# STM32H7A3 register map
File version: 3.4
CPU: CM7 r0p1, little endian, MPU, FPU, 4 interrupt priority bits
Registers are 32-bit, read-write, reset 0x0 unless marked. A register's access mark holds for its fields unless they carry their own. Offsets are from the block's base; [hi:lo] are bit positions; {n}, {i} and the like mark numbered series.

## TAMP — Tamper and backup
Base 0x58004400
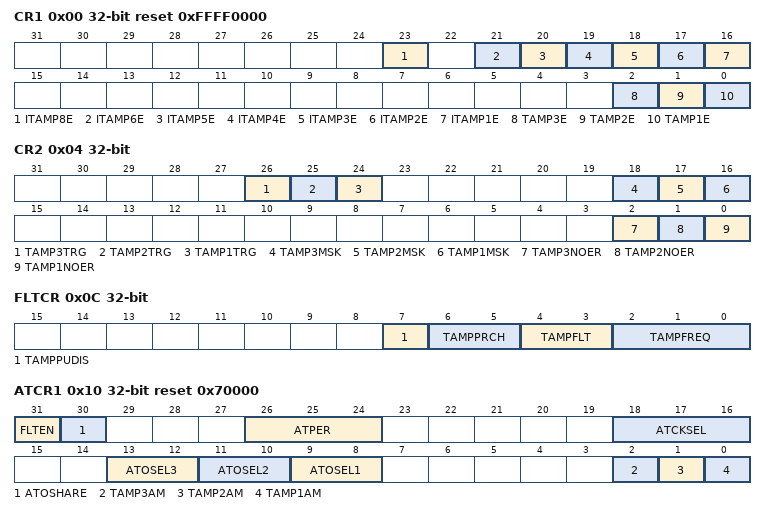
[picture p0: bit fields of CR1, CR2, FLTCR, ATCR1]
0x00 CR1 reset 0xFFFF0000 — TAMP control register 1
  [23] ITAMP8E — Internal tamper 8 enable: monotonic counter overflow
  [21] ITAMP6E — Internal tamper 6 enable: ST manufacturer readout
  [20] ITAMP5E — Internal tamper 5 enable: RTC calendar overflow
  [19] ITAMP4E — Internal tamper 4 enable: HSE monitoring
  [18] ITAMP3E — Internal tamper 3 enable: LSE monitoring
  [17] ITAMP2E — Internal tamper 2 enable: Temperature monitoring
  [16] ITAMP1E — Internal tamper 1 enable: RTC power domain supply monitoring
  [2] TAMP3E — Tamper detection on TAMP_IN3 enable
  [1] TAMP2E — Tamper detection on TAMP_IN2 enable
  [0] TAMP1E — Tamper detection on TAMP_IN1 enable
0x04 CR2 — TAMP control register 2
  [26] TAMP3TRG — Active level for tamper 3 input (active mode disabled) If TAMPFLT = 00 Tamper 3 input rising edge and high level triggers a tamper detection event. If TAMPFLT = 00 Tamper 3 input falling edge and low level triggers a tamper detection event.
  [25] TAMP2TRG — Active level for tamper 2 input (active mode disabled) If TAMPFLT = 00 Tamper 2 input rising edge and high level triggers a tamper detection event. If TAMPFLT = 00 Tamper 2 input falling edge and low level triggers a tamper detection event.
  [24] TAMP1TRG — Active level for tamper 1 input (active mode disabled) If TAMPFLT = 00 Tamper 1 input rising edge and high level triggers a tamper detection event. If TAMPFLT = 00 Tamper 1 input falling edge and low level triggers a tamper detection event.
  [18] TAMP3MSK — Tamper 3 mask The tamper 3 interrupt must not be enabled when TAMP3MSK is set.
  [17] TAMP2MSK — Tamper 2 mask The tamper 2 interrupt must not be enabled when TAMP2MSK is set.
  [16] TAMP1MSK — Tamper 1 mask The tamper 1 interrupt must not be enabled when TAMP1MSK is set.
  [2] TAMP3NOER — Tamper 3 no erase
  [1] TAMP2NOER — Tamper 2 no erase
  [0] TAMP1NOER — Tamper 1 no erase
0x0C FLTCR — TAMP filter control register
  [7] TAMPPUDIS — TAMP_INx pull-up disable This bit determines if each of the TAMPx pins are precharged before each sample.
  [6:5] TAMPPRCH — TAMP_INx precharge duration These bit determines the duration of time during which the pull-up/is activated before each sample. TAMPPRCH is valid for each of the TAMP_INx inputs.
  [4:3] TAMPFLT — TAMP_INx filter count These bits determines the number of consecutive samples at the specified level (TAMP*TRG) needed to activate a tamper event. TAMPFLT is valid for each of the TAMP_INx inputs.
  [2:0] TAMPFREQ — Tamper sampling frequency Determines the frequency at which each of the TAMP_INx inputs are sampled.
0x10 ATCR1 reset 0x70000 — TAMP active tamper control register 1
  [31] FLTEN — Active tamper filter enable
  [30] ATOSHARE — Active tamper output sharing
  [26:24] ATPER — Active tamper output change period The tamper output is changed every CK_ATPER = (2ATPER x CK_ATPRE) cycles. Refer to .
  [18:16] ATCKSEL — Active tamper RTC asynchronous prescaler clock selection These bits selects the RTC asynchronous prescaler stage output.The selected clock is CK_ATPRE. fCK_ATPRE = fRTCCLK / 2ATCKSEL when (PREDIV_A+1) = 128. ... Note: These bits can be written only when all active tampers are disabled. The write protection remains for up to 1.5 ck_atpre cycles after all the active tampers are disable.
  [13:12] ATOSEL3 — Active tamper shared output 3 selection The selected output must be available in the package pinout
  [11:10] ATOSEL2 — Active tamper shared output 2 selection The selected output must be available in the package pinout
  [9:8] ATOSEL1 — Active tamper shared output 1 selection The selected output must be available in the package pinout
  [2] TAMP3AM — Tamper 3 active mode
  [1] TAMP2AM — Tamper 2 active mode
  [0] TAMP1AM — Tamper 1 active mode
0x14 ATSEEDR wo — TAMP active tamper seed register
  [31:0] SEED — Pseudo-random generator seed value This register must be written four times with 32-bit values to provide the 128-bit seed to the PRNG. Writing to this register automatically sends the seed value to the PRNG.
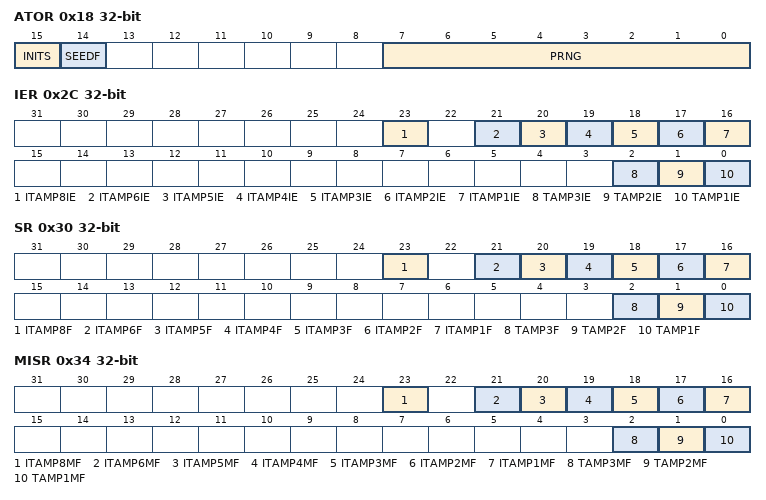
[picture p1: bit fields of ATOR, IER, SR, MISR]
0x18 ATOR ro — TAMP active tamper output register
  [15] INITS — Active tamper initialization status This flag is set by hardware when the PRNG has absorbed the first 128-bit seed, meaning that the enabled active tampers are functional. This flag is left unchanged when the active tampers are disabled.
  [14] SEEDF — Seed running flag This flag is set by hardware when a new seed is written in the TAMP_ATSEEDR. It is cleared by hardware when the PRNG has absorbed this new seed, and by system reset. The TAMP APB cock must not be switched off as long as SEEDF is set.
  [7:0] PRNG — Pseudo-random generator value This field provides the values of the PRNG output. Because of potential inconsistencies due to synchronization delays, PRNG must be read at least twice. The read value is correct if it is equal to previous read value.
0x2C IER — TAMP interrupt enable register
  [23] ITAMP8IE — Internal tamper 8 interrupt enable: monotonic counter overflow
  [21] ITAMP6IE — Internal tamper 6 interrupt enable: ST manufacturer readout
  [20] ITAMP5IE — Internal tamper 5 interrupt enable: RTC calendar overflow
  [19] ITAMP4IE — Internal tamper 4 interrupt enable: HSE monitoring
  [18] ITAMP3IE — Internal tamper 3 interrupt enable: LSE monitoring
  [17] ITAMP2IE — Internal tamper 2 interrupt enable: Temperature monitoring
  [16] ITAMP1IE — Internal tamper 1 interrupt enable: RTC power domain supply monitoring
  [2] TAMP3IE — Tamper 3 interrupt enable
  [1] TAMP2IE — Tamper 2 interrupt enable
  [0] TAMP1IE — Tamper 1 interrupt enable
0x30 SR ro — TAMP status register
  [23] ITAMP8F — Monotonic counter overflow tamper flag This flag is set by hardware when a tamper detection event is detected on the internal tamper 8.
  [21] ITAMP6F — ST manufacturer readout tamper detection flag This flag is set by hardware when a tamper detection event is detected on the internal tamper 6.
  [20] ITAMP5F — RTC calendar overflow tamper detection flag This flag is set by hardware when a tamper detection event is detected on the internal tamper 5.
  [19] ITAMP4F — HSE monitoring tamper detection flag This flag is set by hardware when a tamper detection event is detected on the internal tamper 4.
  [18] ITAMP3F — LSE monitoring tamper detection flag This flag is set by hardware when a tamper detection event is detected on the internal tamper 3.
  [17] ITAMP2F — Temperature monitoring tamper detection flag This flag is set by hardware when a tamper detection event is detected on the internal tamper 2.
  [16] ITAMP1F — RTC power domain voltage monitoring tamper detection flag This flag is set by hardware when a tamper detection event is detected on the internal tamper 1.
  [2] TAMP3F — TAMP3 detection flag This flag is set by hardware when a tamper detection event is detected on the TAMP3 input.
  [1] TAMP2F — TAMP2 detection flag This flag is set by hardware when a tamper detection event is detected on the TAMP2 input.
  [0] TAMP1F — TAMP1 detection flag This flag is set by hardware when a tamper detection event is detected on the TAMP1 input.
0x34 MISR ro — TAMP masked interrupt status register
  [23] ITAMP8MF — Monotonic counter overflow interrupt masked flag This flag is set by hardware when the internal tamper 8 interrupt is raised.
  [21] ITAMP6MF — ST manufacturer readout tamper interrupt masked flag This flag is set by hardware when the internal tamper 6 interrupt is raised.
  [20] ITAMP5MF — RTC calendar overflow tamper interrupt masked flag This flag is set by hardware when the internal tamper 5 interrupt is raised.
  [19] ITAMP4MF — HSE monitoring tamper interrupt masked flag This flag is set by hardware when the internal tamper 4 interrupt is raised.
  [18] ITAMP3MF — LSE monitoring tamper interrupt masked flag This flag is set by hardware when the internal tamper 3 interrupt is raised.
  [17] ITAMP2MF — Temperature monitoring tamper interrupt masked flag This flag is set by hardware when the internal tamper 2 interrupt is raised.
  [16] ITAMP1MF — RTC power domain voltage monitoring tamper interrupt masked flag This flag is set by hardware when the internal tamper 1 interrupt is raised.
  [2] TAMP3MF — TAMP3 interrupt masked flag This flag is set by hardware when the tamper 3 interrupt is raised.
  [1] TAMP2MF — TAMP2 interrupt masked flag This flag is set by hardware when the tamper 2 interrupt is raised.
  [0] TAMP1MF — TAMP1 interrupt masked flag This flag is set by hardware when the tamper 1 interrupt is raised.
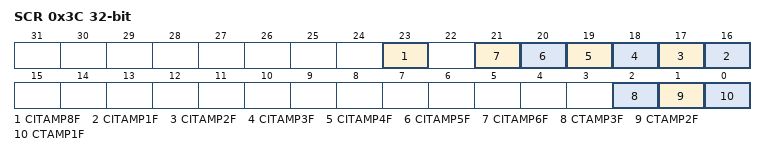
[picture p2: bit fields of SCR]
0x3C SCR wo — TAMP status clear register
  [23] CITAMP8F — Clear ITAMP8 detection flag Writing 1 in this bit clears the ITAMP8F bit in the TAMP_SR register.
  [n+15] CITAMP{n}F (n=1..6) — Clear ITAMP{n} detection flag Writing 1 in this bit clears the ITAMP{n}F bit in the TAMP_SR register.
  [2] CTAMP3F — Clear TAMP3 detection flag Writing 1 in this bit clears the TAMP3F bit in the TAMP_SR register.
  [1] CTAMP2F — Clear TAMP2 detection flag Writing 1 in this bit clears the TAMP2F bit in the TAMP_SR register.
  [0] CTAMP1F — Clear TAMP1 detection flag Writing 1 in this bit clears the TAMP1F bit in the TAMP_SR register.
0x40 COUNTR ro — TAMP monotonic counter register
  [31:0] COUNT — This register is read-only only and is incremented by one when a write access is done to this register. This register cannot roll-over and is frozen when reaching the maximum value.
0x50 CFGR — TAMP configuration register
  [0] OUT3_RMP — TAMP_OUT3 mapping
{0x100+4i} BKP{i}R (i=0..31) — TAMP backup {i} register
  [31:0] BKP — The application can write or read data to and from these registers. They are powered-on by VBAT when VDD is switched off, so that they are not reset by System reset, and their contents remain valid when the device operates in low-power mode. In the default configuration this register is reset on a tamper detection event. It is forced to reset value as long as there is at least one internal or external tamper flag being set. This register is also reset when the readout protection (RDP) is disabled.
